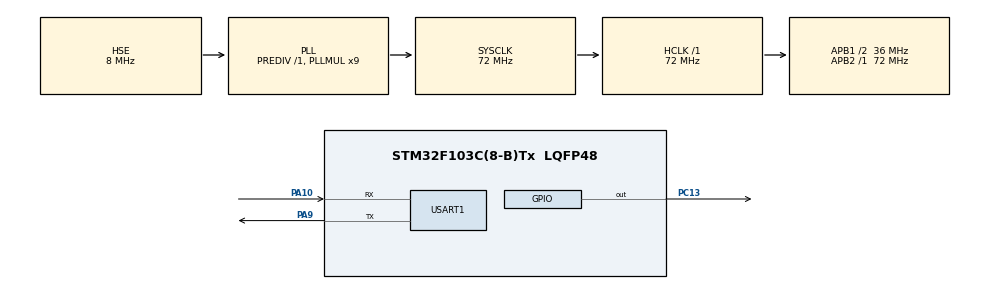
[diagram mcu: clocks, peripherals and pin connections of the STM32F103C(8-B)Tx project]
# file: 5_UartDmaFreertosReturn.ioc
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Dma.Request0=USART1_RX
Dma.Request1=USART1_TX
Dma.USART1_RX.0.Direction=DMA_PERIPH_TO_MEMORY
Dma.USART1_RX.0.Instance=DMA1_Channel5
Dma.USART1_RX.0.MemDataAlignment=DMA_MDATAALIGN_BYTE
Dma.USART1_RX.0.MemInc=DMA_MINC_ENABLE
Dma.USART1_RX.0.Mode=DMA_NORMAL
Dma.USART1_RX.0.PeriphDataAlignment=DMA_PDATAALIGN_BYTE
Dma.USART1_RX.0.PeriphInc=DMA_PINC_DISABLE
Dma.USART1_RX.0.Priority=DMA_PRIORITY_MEDIUM
Dma.USART1_TX.1.Direction=DMA_MEMORY_TO_PERIPH
Dma.USART1_TX.1.Instance=DMA1_Channel4
Dma.USART1_TX.1.MemDataAlignment=DMA_MDATAALIGN_BYTE
Dma.USART1_TX.1.MemInc=DMA_MINC_ENABLE
Dma.USART1_TX.1.Mode=DMA_NORMAL
Dma.USART1_TX.1.PeriphDataAlignment=DMA_PDATAALIGN_BYTE
Dma.USART1_TX.1.PeriphInc=DMA_PINC_DISABLE
Dma.USART1_TX.1.Priority=DMA_PRIORITY_MEDIUM
FREERTOS.Queues01=UartQueue,16,uint16_t,0,Dynamic,NULL,NULL
FREERTOS.Tasks01=UartTask,24,256,Start_UartTask,Default,NULL,Dynamic,NULL,NULL;LedTask,8,128,Start_LedTask,Default,NULL,Dynamic,NULL,NULL
Mcu.Family=STM32F1
Mcu.Name=STM32F103C(8-B)Tx
Mcu.Package=LQFP48
NVIC.DMA1_Channel4_IRQn=true\:5\:0\:false\:false\:true\:true\:false\:true\:true
NVIC.DMA1_Channel5_IRQn=true\:5\:0\:false\:false\:true\:true\:false\:true\:true
NVIC.PriorityGroup=NVIC_PRIORITYGROUP_4
NVIC.TIM4_IRQn=true\:15\:0\:false\:false\:true\:false\:false\:true\:true
NVIC.TimeBase=TIM4_IRQn
NVIC.TimeBaseIP=TIM4
NVIC.USART1_IRQn=true\:5\:0\:false\:false\:true\:true\:true\:true\:true
PA10.Mode=Asynchronous
PA10.Signal=USART1_RX
PA13.Mode=Serial_Wire
PA13.Signal=SYS_JTMS-SWDIO
PA14.Mode=Serial_Wire
PA14.Signal=SYS_JTCK-SWCLK
PA9.Mode=Asynchronous
PA9.Signal=USART1_TX
PC13-TAMPER-RTC.PinState=GPIO_PIN_SET
PC13-TAMPER-RTC.Signal=GPIO_Output
PD0-OSC_IN.Mode=HSE-External-Oscillator
PD0-OSC_IN.Signal=RCC_OSC_IN
PD1-OSC_OUT.Mode=HSE-External-Oscillator
PD1-OSC_OUT.Signal=RCC_OSC_OUT
ProjectManager.HeapSize=0x200
ProjectManager.StackSize=0x400
ProjectManager.TargetToolchain=MDK-ARM V5.32
RCC.AHBFreq_Value=72000000
RCC.APB1CLKDivider=RCC_HCLK_DIV2
RCC.APB1Freq_Value=36000000
RCC.APB1TimFreq_Value=72000000
RCC.APB2Freq_Value=72000000
RCC.APB2TimFreq_Value=72000000
RCC.EnbaleCSS=true
RCC.HCLKFreq_Value=72000000
RCC.PLLMUL=RCC_PLL_MUL9
RCC.PLLSourceVirtual=RCC_PLLSOURCE_HSE
RCC.SYSCLKFreq_VALUE=72000000
RCC.SYSCLKSource=RCC_SYSCLKSOURCE_PLLCLK
RCC.USBFreq_Value=72000000
USART1.VirtualMode=VM_ASYNC
VP_FREERTOS_VS_CMSIS_V2.Mode=CMSIS_V2
VP_SYS_VS_tim4.Mode=TIM4
board=custom

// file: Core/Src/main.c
/* USER CODE BEGIN Header */
/**
  ******************************************************************************
  * @file           : main.c
  * @brief          : Main program body
  ******************************************************************************
  * @attention
  *
  * Copyright (c) 2025 STMicroelectronics.
  * All rights reserved.
  *
  * This software is licensed under terms that can be found in the LICENSE file
  * in the root directory of this software component.
  * If no LICENSE file comes with this software, it is provided AS-IS.
  *
  ******************************************************************************
  */
/* USER CODE END Header */
#include "main.h"
#include "cmsis_os.h"
#include "dma.h"
#include "usart.h"
#include "gpio.h"

void SystemClock_Config(void);
void MX_FREERTOS_Init(void);

int main(void)
{

  /* MCU Configuration--------------------------------------------------------*/

  /* Reset of all peripherals, Initializes the Flash interface and the Systick. */
  HAL_Init();

  /* Configure the system clock */
  SystemClock_Config();

  /* Initialize all configured peripherals */
  MX_GPIO_Init();
  MX_DMA_Init();
  MX_USART1_UART_Init();

  /* Init scheduler */
  osKernelInitialize();  /* Call init function for freertos objects (in cmsis_os2.c) */
  MX_FREERTOS_Init();

  /* Start scheduler */
  osKernelStart();

  /* We should never get here as control is now taken by the scheduler */

  /* Infinite loop */
  /* USER CODE BEGIN WHILE */
  while (1)
  {
    // HAL_GPIO_TogglePin(GPIOC, GPIO_PIN_13);
    /* USER CODE END WHILE */

  }
}

void SystemClock_Config(void)
{
  RCC_OscInitTypeDef RCC_OscInitStruct = {0};
  RCC_ClkInitTypeDef RCC_ClkInitStruct = {0};

  /** Initializes the RCC Oscillators according to the specified parameters
  * in the RCC_OscInitTypeDef structure.
  */
  RCC_OscInitStruct.OscillatorType = RCC_OSCILLATORTYPE_HSE;
  RCC_OscInitStruct.HSEState = RCC_HSE_ON;
  RCC_OscInitStruct.HSEPredivValue = RCC_HSE_PREDIV_DIV1;
  RCC_OscInitStruct.HSIState = RCC_HSI_ON;
  RCC_OscInitStruct.PLL.PLLState = RCC_PLL_ON;
  RCC_OscInitStruct.PLL.PLLSource = RCC_PLLSOURCE_HSE;
  RCC_OscInitStruct.PLL.PLLMUL = RCC_PLL_MUL9;
  if (HAL_RCC_OscConfig(&RCC_OscInitStruct) != HAL_OK)
  {
    Error_Handler();
  }

  /** Initializes the CPU, AHB and APB buses clocks
  */
  RCC_ClkInitStruct.ClockType = RCC_CLOCKTYPE_HCLK|RCC_CLOCKTYPE_SYSCLK
                              |RCC_CLOCKTYPE_PCLK1|RCC_CLOCKTYPE_PCLK2;
  RCC_ClkInitStruct.SYSCLKSource = RCC_SYSCLKSOURCE_PLLCLK;
  RCC_ClkInitStruct.AHBCLKDivider = RCC_SYSCLK_DIV1;
  RCC_ClkInitStruct.APB1CLKDivider = RCC_HCLK_DIV2;
  RCC_ClkInitStruct.APB2CLKDivider = RCC_HCLK_DIV1;

  if (HAL_RCC_ClockConfig(&RCC_ClkInitStruct, FLASH_LATENCY_2) != HAL_OK)
  {
    Error_Handler();
  }

  /** Enables the Clock Security System
  */
  HAL_RCC_EnableCSS();
}

/* USER CODE BEGIN 4 */

void HAL_UART_TxCpltCallback(UART_HandleTypeDef *huart)
{
  if (huart->Instance == USART1)
  {
    //此处翻转，是否多余？；；在freertos-LEDTask中，计数后翻转更好，毕竟是LED任务
    //上一句否掉，就在这里发吧，正好是“发送”完成后调用
    HAL_GPIO_TogglePin(GPIOC, GPIO_PIN_13); // 翻转LED表示DMA完成
  }
}

/* USER CODE END 4 */

void HAL_TIM_PeriodElapsedCallback(TIM_HandleTypeDef *htim)
{
  if (htim->Instance == TIM4)
  {
    HAL_IncTick();
  }
}

void Error_Handler(void)
{
  __disable_irq();
  while (1)
  {
  }
}

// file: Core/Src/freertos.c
/* USER CODE BEGIN Header */
/**
  ******************************************************************************
  * File Name          : freertos.c
  * Description        : Code for freertos applications
  ******************************************************************************
  * @attention
  *
  * Copyright (c) 2025 STMicroelectronics.
  * All rights reserved.
  *
  * This software is licensed under terms that can be found in the LICENSE file
  * in the root directory of this software component.
  * If no LICENSE file comes with this software, it is provided AS-IS.
  *
  ******************************************************************************
  */
/* USER CODE END Header */

#include "FreeRTOS.h"
#include "task.h"
#include "main.h"
#include "cmsis_os.h"

/* USER CODE BEGIN Includes */

#include "usart.h"
#include "stdio.h"
#include "string.h"

/* USER CODE END Includes */

/* USER CODE BEGIN Variables */
// volatile uint8_t counter = 0;

/* USER CODE END Variables */
/* Definitions for UartTask */
osThreadId_t UartTaskHandle;
const osThreadAttr_t UartTask_attributes = {
  .name = "UartTask",
  .stack_size = 256 * 4,
  .priority = (osPriority_t) osPriorityNormal,
};
/* Definitions for LedTask */
osThreadId_t LedTaskHandle;
const osThreadAttr_t LedTask_attributes = {
  .name = "LedTask",
  .stack_size = 128 * 4,
  .priority = (osPriority_t) osPriorityLow,
};
/* Definitions for UartQueue */
osMessageQueueId_t UartQueueHandle;
const osMessageQueueAttr_t UartQueue_attributes = {
  .name = "UartQueue"
};

void Start_UartTask(void *argument);
void Start_LedTask(void *argument);

void MX_FREERTOS_Init(void); /* (MISRA C 2004 rule 8.1) */

void MX_FREERTOS_Init(void) {

  /* Create the queue(s) */
  /* creation of UartQueue */
  UartQueueHandle = osMessageQueueNew (16, sizeof(uint16_t), &UartQueue_attributes);

  /* Create the thread(s) */
  /* creation of UartTask */
  UartTaskHandle = osThreadNew(Start_UartTask, NULL, &UartTask_attributes);

  /* creation of LedTask */
  LedTaskHandle = osThreadNew(Start_LedTask, NULL, &LedTask_attributes);

}

void Start_UartTask(void *argument)
{
  /* USER CODE BEGIN Start_UartTask */

  char txBuf[64];
  uint8_t recvData;

  /* Infinite loop */
  for(;;)
  {
    if (osMessageQueueGet(UartQueueHandle, &recvData, NULL, osWaitForever) == osOK)
    {
      snprintf(txBuf, sizeof(txBuf), "Counter = %d\r\n", recvData);

      if (huart1.gState == HAL_UART_STATE_READY)
      {
        HAL_UART_Transmit_DMA(&huart1, (uint8_t *)txBuf, strlen(txBuf));
      }
    }
  }
  /* USER CODE END Start_UartTask */
}

void Start_LedTask(void *argument)
{
  /* USER CODE BEGIN Start_LedTask */

  uint8_t counter = 0;

  /* Infinite loop */
  for(;;)
  {
    //这里的LedTask，或许现在换成CountTask更合适hh

    osDelay(500);
    // HAL_GPIO_TogglePin(GPIOC, GPIO_PIN_13);
    osMessageQueuePut(UartQueueHandle, &counter, 0, 0);
    // osMessageQueuePut()
    counter++;
    //计数完成后翻转LED
    // HAL_GPIO_TogglePin(GPIOC, GPIO_PIN_13);
  }
  /* USER CODE END Start_LedTask */
}
